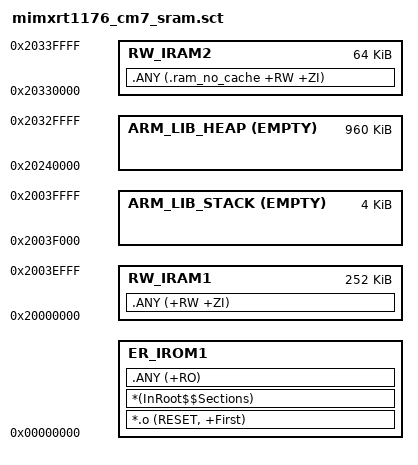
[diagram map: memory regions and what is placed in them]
;*********************************************************************
;* i.MX RT1176 linker scatter file (running code from internal SRAM) *
;*********************************************************************

LR_IROM1 0x00000000 0x40000
{
   ER_IROM1 0x00000000
   {
      *.o (RESET, +First)
      *(InRoot$$Sections)
      .ANY (+RO)
   }
   
   RW_IRAM1 0x20000000 0x3F000
   {
      .ANY (+RW +ZI)
   }
   
   ARM_LIB_STACK 0x20040000 EMPTY -0x1000
   {
   }
   
   ARM_LIB_HEAP 0x20240000 EMPTY 0xF0000
   {
   }
   
   RW_IRAM2 0x20330000 0x10000
   {
      .ANY (.ram_no_cache +RW +ZI)
   }
}
